# FEATURES register map
svd_converter golden fixture
Registers are 32-bit, read-write, no defined reset value unless marked. A register's access mark holds for its fields unless they carry their own. Offsets are from the block's base; lines under a group give offsets from that group; [hi:lo] are bit positions; {n}, {i} and the like mark numbered series; 'fields as' and 'values as' point back to an identical list; <NAME> marks a mode.

## Memory map
0x00000000 SPARE — Interrupt only: no registers, base address 0
0x40000000 CTRLP — Plain peripheral: one instance, every kind of register
0x40001000 TC0 — A peripheral with a derived instance
0x40001400 TC1
0x40002000 SERCOM — Modes: clusters without dim become peripherals of their own
0x40003000 INHERIT — Register properties passed down (device, peripheral, cluster, register), derivedFrom by SVD name, resetMask

## Interrupts
0 CTRLP
1 TC (TC0, TC1)
3 SERCOM
4 SPARE

## CTRLP — Plain peripheral: one instance, every kind of register
Base 0x40000000
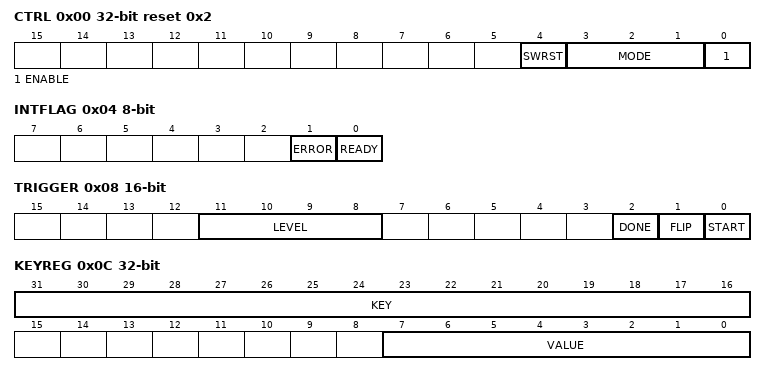
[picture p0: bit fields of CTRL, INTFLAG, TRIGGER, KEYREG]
0x00 CTRL reset 0x2 — Enum field, plain field, an accepted write-only strobe next to them
  [4] SWRST wo — Software reset
  [3:1] MODE — Operating mode
    0=OFF; 1=SLOW; 2=FAST
  [0] ENABLE
0x04 INTFLAG 8-bit — 8-bit register of write-one-to-clear flags
  [1] ERROR write-1-clears, [0] READY write-1-clears
0x08 TRIGGER 16-bit — 16-bit register: a write-only trigger whose 0 does nothing, toggle and zero-to-clear fields
  [11:8] LEVEL, [2] DONE write-0-clears, [1] FLIP write-1-toggles, [0] START wo write-1-sets
0x0C KEYREG — A key field: every write must carry it
  [31:16] KEY wo range 0x5AFE..0x5AFE, [7:0] VALUE
0x10 FIFO ro — Reading pops: a read with a side effect
  [31:0] DATA read-clears
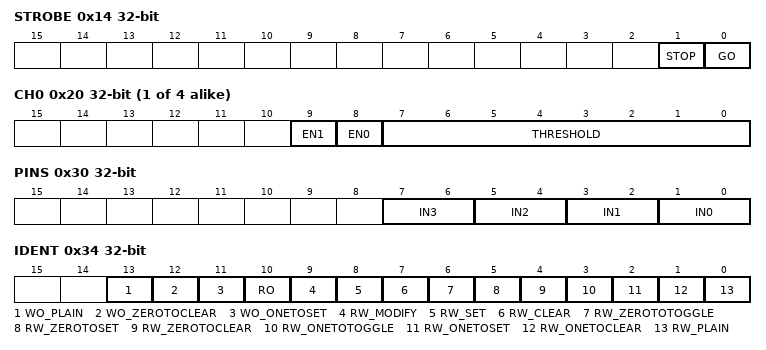
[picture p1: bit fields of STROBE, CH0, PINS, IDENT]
0x14 STROBE wo — No readable field: a write-only register
  [1] STOP, [0] GO
0x18 BUF — No fields: one value, FULLREGISTER only
{0x20+4i} CH{i} (i=0..3) — A dim register
  [n+8] EN{n} (n=0..1), [7:0] THRESHOLD
0x30 PINS — A dim field
  [2n+1:2n] IN{n} (n=0..3)
0x34 IDENT — One field per access and modifiedWriteValues: the identity cross-check (Kvasir_SDK generated_registers_tests.cpp lists the same rows)
  [13] WO_PLAIN wo, [12] WO_ZEROTOCLEAR wo write-0-clears, [11] WO_ONETOSET wo write-1-sets, [10] RO ro, [9] RW_MODIFY, [8] RW_SET write-sets, [7] RW_CLEAR write-clears, [6] RW_ZEROTOTOGGLE write-0-toggles, [5] RW_ZEROTOSET write-0-sets, [4] RW_ZEROTOCLEAR write-0-clears, [3] RW_ONETOTOGGLE write-1-toggles, [2] RW_ONETOSET write-1-sets, [1] RW_ONETOCLEAR write-1-clears, [0] RW_PLAIN
{0x40+0x10*i} GRP[{i}] (i=0..1) group — A register group; its second register is named like the group
  0x00 CFG
    [3:0] SEL
  0x04 GRP — Named like its group
    [7:0] EVT

## TC0 — A peripheral with a derived instance
Base 0x40001000
Same registers: TC1 0x40001400
0x00 COUNT 16-bit reset 0x0

## SERCOM — Modes: clusters without dim become peripherals of their own
Base 0x40002000
0x00 UART group
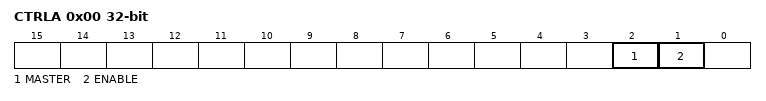
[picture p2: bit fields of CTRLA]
  0x00 CTRLA
    [1] ENABLE
0x00 SPI group
  0x00 CTRLA
    [2] MASTER, [1] ENABLE

## INHERIT — Register properties passed down (device, peripheral, cluster, register), derivedFrom by SVD name, resetMask
Base 0x40003000
0x00 STATUS 16-bit ro — Inherits the peripheral's size (16) and access (read-only)
  [3:0] LEVEL
0x02 CTRL_A 16-bit — A base whose C name (displayName) differs from its SVD name
  [0] EN
0x04 CTRL_B 16-bit — A base whose C name (displayName) differs from its SVD name
  [0] EN
0x06 DIV 16-bit — resetMask 0: no defined reset value, so no overrideDefaults
  [1:0] MODE
    0=OFF; 1=ON
0x08 PART 16-bit reset 0x2 (reset mask 0x2) — resetMask covers bit 1 only: the field's defined bit is checked
  [1:0] MODE
    2=A; 3=B
0x0A ID 16-bit ro — No fields, inherits read-only: FULLREGISTER is read-only
0x0C TXDATA 16-bit wo — No fields, write-only: FULLREGISTER is write-only
0x0E ONCE 16-bit write-once — No fields, writeOnce: FULLREGISTER is write-only
{0x10+i} LANE.CFG[{i}] (i=0..1) group — A dim cluster with its own size and access, and a name sanitizeName changes
  0x00 SEL 8-bit
    [1:0] SRC
